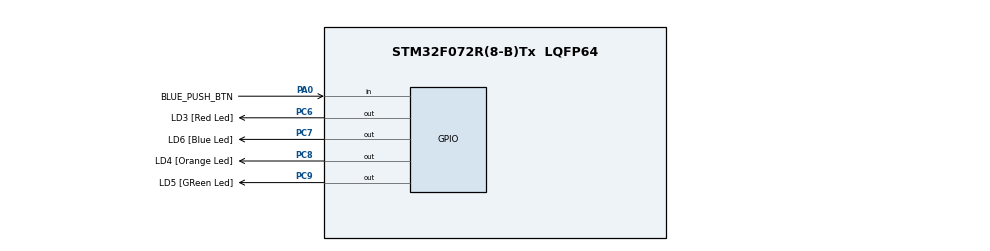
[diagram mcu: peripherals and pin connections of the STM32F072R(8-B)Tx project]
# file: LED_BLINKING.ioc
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Mcu.Family=STM32F0
Mcu.Name=STM32F072R(8-B)Tx
Mcu.Package=LQFP64
PA0.GPIO_Label=BLUE_PUSH_BTN
PA0.Signal=GPIO_Input
PA11.GPIO_Label=USBF4_DM
PA11.Signal=USB_DM
PA12.GPIO_Label=USBF4_DP
PA12.Signal=USB_DP
PA14.GPIO_Label=SWCLK
PA14.Signal=SYS_SWCLK
PA2.Signal=TSC_G1_IO3
PA3.Signal=TSC_G1_IO4
PA6.Signal=TSC_G2_IO3
PA7.Signal=TSC_G2_IO4
PB0.Signal=TSC_G3_IO2
PB1.Signal=TSC_G3_IO3
PB10.GPIO_Label=I2C2_SCL[EXT/RF-E2P_SCL]
PB10.Signal=I2C2_SCL
PB11.GPIO_Label=I2C2_SDA[EXT/RF-E2P_SDA]
PB11.Signal=I2C2_SDA
PB13.GPIO_Label=SPI2_SCK [L3GD20_SCL/SPC]
PB13.Signal=SPI2_SCK
PB14.GPIO_Label=SPI2_MISO [L3GD20_SDO]
PB14.Signal=SPI2_MISO
PB15.GPIO_Label=SPI2_MOSI [L3GD20_SDA/SDI]
PB15.Signal=SPI2_MOSI
PC6.GPIO_Label=LD3 [Red Led]
PC6.Signal=GPIO_Output
PC7.GPIO_Label=LD6 [Blue Led]
PC7.Signal=GPIO_Output
PC8.GPIO_Label=LD4 [Orange Led]
PC8.Signal=GPIO_Output
PC9.GPIO_Label=LD5 [GReen Led]
PC9.Signal=GPIO_Output
ProjectManager.HeapSize=0x200
ProjectManager.StackSize=0x400
ProjectManager.TargetToolchain=STM32CubeIDE
board=STM32F072B-DISCO

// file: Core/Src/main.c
/* USER CODE BEGIN Header */
/**
  ******************************************************************************
  * @file           : main.c
  * @brief          : Main program body
  ******************************************************************************
  * @attention
  *
  * <h2><center>&copy; Copyright (c) 2024 STMicroelectronics.
  * All rights reserved.</center></h2>
  *
  * This software component is licensed by ST under BSD 3-Clause license,
  * the "License"; You may not use this file except in compliance with the
  * License. You may obtain a copy of the License at:
  *                        opensource.org/licenses/BSD-3-Clause
  *
  ******************************************************************************
  */
/* USER CODE END Header */
#include "main.h"

void SystemClock_Config(void);
static void MX_GPIO_Init(void);

int main(void)
{

  /* MCU Configuration--------------------------------------------------------*/

  /* Reset of all peripherals, Initializes the Flash interface and the Systick. */
  HAL_Init();

  /* Configure the system clock */
  SystemClock_Config();

  /* Initialize all configured peripherals */
  MX_GPIO_Init();

  /* Infinite loop */
  while (1)
  {

    /* USER CODE BEGIN 3 */
	  if(HAL_GPIO_ReadPin(BLUE_PUSH_BTN_GPIO_Port, GPIO_PIN_0)== GPIO_PIN_SET){
		  HAL_GPIO_WritePin(LD3_GPIO_Port, LD3_Pin, GPIO_PIN_SET);
	  }
	  else
	  {
		  HAL_GPIO_WritePin(LD3_GPIO_Port, LD3_Pin, GPIO_PIN_RESET);
	  }
 }
  /* USER CODE END 3 */
}

void SystemClock_Config(void)
{
  RCC_OscInitTypeDef RCC_OscInitStruct = {0};
  RCC_ClkInitTypeDef RCC_ClkInitStruct = {0};

  /** Initializes the RCC Oscillators according to the specified parameters
  * in the RCC_OscInitTypeDef structure.
  */
  RCC_OscInitStruct.OscillatorType = RCC_OSCILLATORTYPE_HSI;
  RCC_OscInitStruct.HSIState = RCC_HSI_ON;
  RCC_OscInitStruct.HSICalibrationValue = RCC_HSICALIBRATION_DEFAULT;
  RCC_OscInitStruct.PLL.PLLState = RCC_PLL_NONE;
  if (HAL_RCC_OscConfig(&RCC_OscInitStruct) != HAL_OK)
  {
    Error_Handler();
  }
  /** Initializes the CPU, AHB and APB buses clocks
  */
  RCC_ClkInitStruct.ClockType = RCC_CLOCKTYPE_HCLK|RCC_CLOCKTYPE_SYSCLK
                              |RCC_CLOCKTYPE_PCLK1;
  RCC_ClkInitStruct.SYSCLKSource = RCC_SYSCLKSOURCE_HSI;
  RCC_ClkInitStruct.AHBCLKDivider = RCC_SYSCLK_DIV1;
  RCC_ClkInitStruct.APB1CLKDivider = RCC_HCLK_DIV1;

  if (HAL_RCC_ClockConfig(&RCC_ClkInitStruct, FLASH_LATENCY_0) != HAL_OK)
  {
    Error_Handler();
  }
}

static void MX_GPIO_Init(void)
{
  GPIO_InitTypeDef GPIO_InitStruct = {0};

  /* GPIO Ports Clock Enable */
  __HAL_RCC_GPIOA_CLK_ENABLE();
  __HAL_RCC_GPIOB_CLK_ENABLE();
  __HAL_RCC_GPIOC_CLK_ENABLE();

  /*Configure GPIO pin Output Level */
  HAL_GPIO_WritePin(GPIOC, LD3_Pin|LD6_Pin|LD4_Pin|LD5_Pin, GPIO_PIN_RESET);

  /*Configure GPIO pin : BLUE_PUSH_BTN_Pin */
  GPIO_InitStruct.Pin = BLUE_PUSH_BTN_Pin;
  GPIO_InitStruct.Mode = GPIO_MODE_INPUT;
  GPIO_InitStruct.Pull = GPIO_NOPULL;
  HAL_GPIO_Init(BLUE_PUSH_BTN_GPIO_Port, &GPIO_InitStruct);

  /*Configure GPIO pins : PA2 PA3 PA6 PA7 */
  GPIO_InitStruct.Pin = GPIO_PIN_2|GPIO_PIN_3|GPIO_PIN_6|GPIO_PIN_7;
  GPIO_InitStruct.Mode = GPIO_MODE_AF_PP;
  GPIO_InitStruct.Pull = GPIO_NOPULL;
  GPIO_InitStruct.Speed = GPIO_SPEED_FREQ_LOW;
  GPIO_InitStruct.Alternate = GPIO_AF3_TSC;
  HAL_GPIO_Init(GPIOA, &GPIO_InitStruct);

  /*Configure GPIO pins : PB0 PB1 */
  GPIO_InitStruct.Pin = GPIO_PIN_0|GPIO_PIN_1;
  GPIO_InitStruct.Mode = GPIO_MODE_AF_PP;
  GPIO_InitStruct.Pull = GPIO_NOPULL;
  GPIO_InitStruct.Speed = GPIO_SPEED_FREQ_LOW;
  GPIO_InitStruct.Alternate = GPIO_AF3_TSC;
  HAL_GPIO_Init(GPIOB, &GPIO_InitStruct);

  /*Configure GPIO pins : I2C2_SCL_Pin I2C2_SDA_Pin */
  GPIO_InitStruct.Pin = I2C2_SCL_Pin|I2C2_SDA_Pin;
  GPIO_InitStruct.Mode = GPIO_MODE_AF_OD;
  GPIO_InitStruct.Pull = GPIO_NOPULL;
  GPIO_InitStruct.Speed = GPIO_SPEED_FREQ_HIGH;
  GPIO_InitStruct.Alternate = GPIO_AF1_I2C2;
  HAL_GPIO_Init(GPIOB, &GPIO_InitStruct);

  /*Configure GPIO pins : SPI2_SCK_Pin SPI2_MISO_Pin SPI2_MOSI_Pin */
  GPIO_InitStruct.Pin = SPI2_SCK_Pin|SPI2_MISO_Pin|SPI2_MOSI_Pin;
  GPIO_InitStruct.Mode = GPIO_MODE_AF_PP;
  GPIO_InitStruct.Pull = GPIO_NOPULL;
  GPIO_InitStruct.Speed = GPIO_SPEED_FREQ_HIGH;
  GPIO_InitStruct.Alternate = GPIO_AF0_SPI2;
  HAL_GPIO_Init(GPIOB, &GPIO_InitStruct);

  /*Configure GPIO pins : LD3_Pin LD6_Pin LD4_Pin LD5_Pin */
  GPIO_InitStruct.Pin = LD3_Pin|LD6_Pin|LD4_Pin|LD5_Pin;
  GPIO_InitStruct.Mode = GPIO_MODE_OUTPUT_PP;
  GPIO_InitStruct.Pull = GPIO_NOPULL;
  GPIO_InitStruct.Speed = GPIO_SPEED_FREQ_LOW;
  HAL_GPIO_Init(GPIOC, &GPIO_InitStruct);

}

void Error_Handler(void)
{
  __disable_irq();
  while (1)
  {
  }
}

/************************ (C) COPYRIGHT STMicroelectronics *****END OF FILE****/
